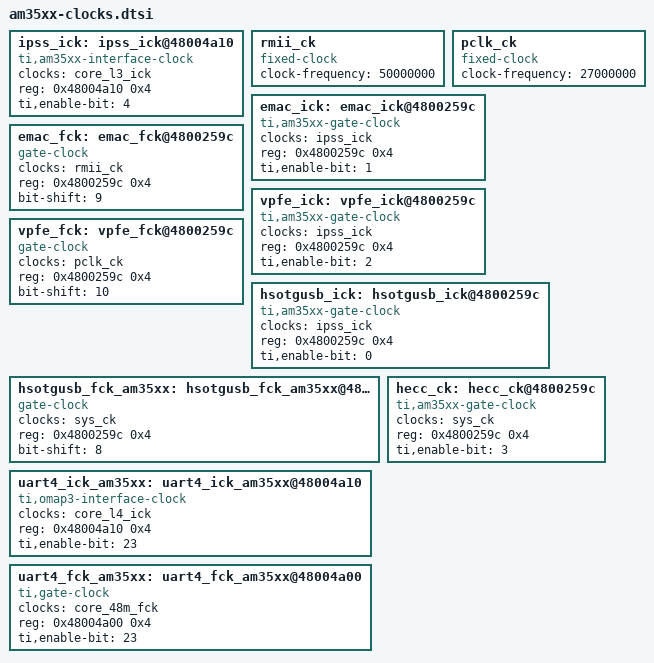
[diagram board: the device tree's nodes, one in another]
/*
 * Device Tree Source for AM35xx clock data
 *
 * Copyright (C) 2013 Texas Instruments, Inc.
 *
 * This program is free software; you can redistribute it and/or modify
 * it under the terms of the GNU General Public License version 2 as
 * published by the Free Software Foundation.
 */

ipss_ick: ipss_ick@48004a10 {
	#clock-cells = <0>;
	compatible = "ti,am35xx-interface-clock";
	clocks = <&core_l3_ick>;
	reg = <0x48004a10 0x4>;
	ti,enable-bit = <4>;
};

rmii_ck: rmii_ck {
	#clock-cells = <0>;
	compatible = "fixed-clock";
	clock-frequency = <50000000>;
};

pclk_ck: pclk_ck {
	#clock-cells = <0>;
	compatible = "fixed-clock";
	clock-frequency = <27000000>;
};

emac_ick: emac_ick@4800259c {
	#clock-cells = <0>;
	compatible = "ti,am35xx-gate-clock";
	clocks = <&ipss_ick>;
	reg = <0x4800259c 0x4>;
	ti,enable-bit = <1>;
};

emac_fck: emac_fck@4800259c {
	#clock-cells = <0>;
	compatible = "gate-clock";
	clocks = <&rmii_ck>;
	reg = <0x4800259c 0x4>;
	bit-shift = <9>;
};

vpfe_ick: vpfe_ick@4800259c {
	#clock-cells = <0>;
	compatible = "ti,am35xx-gate-clock";
	clocks = <&ipss_ick>;
	reg = <0x4800259c 0x4>;
	ti,enable-bit = <2>;
};

vpfe_fck: vpfe_fck@4800259c {
	#clock-cells = <0>;
	compatible = "gate-clock";
	clocks = <&pclk_ck>;
	reg = <0x4800259c 0x4>;
	bit-shift = <10>;
};

hsotgusb_ick: hsotgusb_ick@4800259c {
	#clock-cells = <0>;
	compatible = "ti,am35xx-gate-clock";
	clocks = <&ipss_ick>;
	reg = <0x4800259c 0x4>;
	ti,enable-bit = <0>;
};

hsotgusb_fck_am35xx: hsotgusb_fck_am35xx@4800259c {
	#clock-cells = <0>;
	compatible = "gate-clock";
	clocks = <&sys_ck>;
	reg = <0x4800259c 0x4>;
	bit-shift = <8>;
};

hecc_ck: hecc_ck@4800259c {
	#clock-cells = <0>;
	compatible = "ti,am35xx-gate-clock";
	clocks = <&sys_ck>;
	reg = <0x4800259c 0x4>;
	ti,enable-bit = <3>;
};

uart4_ick_am35xx: uart4_ick_am35xx@48004a10 {
	#clock-cells = <0>;
	compatible = "ti,omap3-interface-clock";
	clocks = <&core_l4_ick>;
	reg = <0x48004a10 0x4>;
	ti,enable-bit = <23>;
};

uart4_fck_am35xx: uart4_fck_am35xx@48004a00 {
	#clock-cells = <0>;
	compatible = "ti,gate-clock";
	clocks = <&core_48m_fck>;
	reg = <0x48004a00 0x4>;
	ti,enable-bit = <23>;
};
